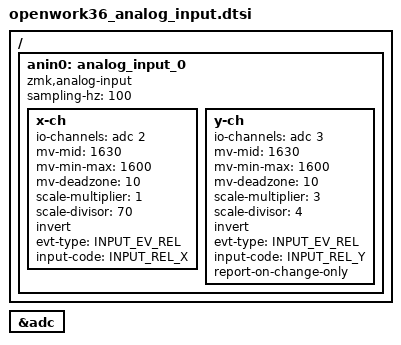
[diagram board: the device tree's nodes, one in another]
#include <zephyr/dt-bindings/input/input-event-codes.h>
/* Reference: https://docs.zephyrproject.org/apidoc/latest/group__input__events.html */

&adc {
	status = "okay";
};

/ {
	anin0: analog_input_0 {
		compatible = "zmk,analog-input";
		sampling-hz = <100>;
		x-ch {
			io-channels = <&adc 2>;
			mv-mid = <1630>;
			mv-min-max = <1600>;
			mv-deadzone = <10>;
			scale-multiplier = <1>;
			scale-divisor = <70>;
			invert;
			evt-type = <INPUT_EV_REL>;
			input-code = <INPUT_REL_X>;
		};
		y-ch {
			io-channels = <&adc 3>;
			mv-mid = <1630>;
			mv-min-max = <1600>;
			mv-deadzone = <10>;
			scale-multiplier = <3>;
			scale-divisor = <4>;
			invert;
			evt-type = <INPUT_EV_REL>;
			input-code = <INPUT_REL_Y>;

			/* enable report mdoe for gamepad axix or knob */
			/* to only call input_report on quantquantized value is updated */
			report-on-change-only;

		};
	};
};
